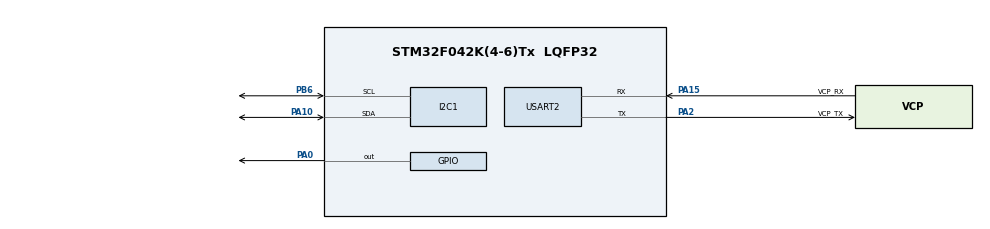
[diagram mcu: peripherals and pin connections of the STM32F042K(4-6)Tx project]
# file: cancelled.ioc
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Mcu.Family=STM32F0
Mcu.Name=STM32F042K(4-6)Tx
Mcu.Package=LQFP32
NVIC.TIM1_BRK_UP_TRG_COM_IRQn=true\:0\:0\:false\:false\:true\:false\:true
NVIC.TimeBase=TIM1_BRK_UP_TRG_COM_IRQn
NVIC.TimeBaseIP=TIM1
PA0.Signal=GPIO_Output
PA10.Mode=I2C
PA10.Signal=I2C1_SDA
PA13.GPIO_Label=SWDIO
PA13.Mode=Serial_Wire
PA13.Signal=SYS_SWDIO
PA14.GPIO_Label=SWCLK
PA14.Mode=Serial_Wire
PA14.Signal=SYS_SWCLK
PA15.GPIO_Label=VCP_RX
PA15.Mode=Asynchronous
PA15.Signal=USART2_RX
PA2.GPIO_Label=VCP_TX
PA2.Mode=Asynchronous
PA2.Signal=USART2_TX
PB6.Mode=I2C
PB6.Signal=I2C1_SCL
PF0-OSC_IN.GPIO_Label=MCO
PF0-OSC_IN.Mode=HSE-External-Clock-Source
PF0-OSC_IN.Signal=RCC_OSC_IN
ProjectManager.HeapSize=0x200
ProjectManager.StackSize=0x400
ProjectManager.TargetToolchain=STM32CubeIDE
USART2.VirtualMode-Asynchronous=VM_ASYNC
VP_SYS_VS_tim1.Mode=TIM1
board=NUCLEO-F042K6

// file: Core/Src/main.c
/* USER CODE BEGIN Header */
/**
  ******************************************************************************
  * @file           : main.c
  * @brief          : Main program body
  ******************************************************************************
  * @attention
  *
  * <h2><center>&copy; Copyright (c) 2020 STMicroelectronics.
  * All rights reserved.</center></h2>
  *
  * This software component is licensed by ST under BSD 3-Clause license,
  * the "License"; You may not use this file except in compliance with the
  * License. You may obtain a copy of the License at:
  *                        opensource.org/licenses/BSD-3-Clause
  *
  ******************************************************************************
  */
/* USER CODE END Header */

#include "main.h"

/* USER CODE BEGIN Includes */
#include "matrix.h"
#include "conway.h"
#include "random.h"
#include "rotate.h"
#include "doggo.h"
/* USER CODE END Includes */

I2C_HandleTypeDef hi2c1;

UART_HandleTypeDef huart2;

/* USER CODE BEGIN PV */
uint8_t* active_fbuf;
uint8_t* next_fbuf;
/* USER CODE END PV */

void SystemClock_Config(void);
static void MX_GPIO_Init(void);
static void MX_USART2_UART_Init(void);
static void MX_I2C1_Init(void);

int main(void)
{

  /* MCU Configuration--------------------------------------------------------*/

  /* Reset of all peripherals, Initializes the Flash interface and the Systick. */
  HAL_Init();

  /* Configure the system clock */
  SystemClock_Config();

  /* Initialize all configured peripherals */
  MX_GPIO_Init();
  MX_USART2_UART_Init();
  MX_I2C1_Init();
  /* USER CODE BEGIN 2 */
  init_matrix(&hi2c1);
  init_accel(&hi2c1);
  /* USER CODE END 2 */

  /* Infinite loop */
  while (1)
  {

    /* USER CODE BEGIN 3 */
	  doggo_demo(&hi2c1);
	  conway_demo(&hi2c1);
	  rotate_demo(&hi2c1);

  }
  /* USER CODE END 3 */
}

void SystemClock_Config(void)
{
  RCC_OscInitTypeDef RCC_OscInitStruct = {0};
  RCC_ClkInitTypeDef RCC_ClkInitStruct = {0};
  RCC_PeriphCLKInitTypeDef PeriphClkInit = {0};

  /** Initializes the CPU, AHB and APB busses clocks
  */
  RCC_OscInitStruct.OscillatorType = RCC_OSCILLATORTYPE_HSI;
  RCC_OscInitStruct.HSIState = RCC_HSI_ON;
  RCC_OscInitStruct.HSICalibrationValue = RCC_HSICALIBRATION_DEFAULT;
  RCC_OscInitStruct.PLL.PLLState = RCC_PLL_NONE;
  if (HAL_RCC_OscConfig(&RCC_OscInitStruct) != HAL_OK)
  {
    Error_Handler();
  }
  /** Initializes the CPU, AHB and APB busses clocks
  */
  RCC_ClkInitStruct.ClockType = RCC_CLOCKTYPE_HCLK|RCC_CLOCKTYPE_SYSCLK
                              |RCC_CLOCKTYPE_PCLK1;
  RCC_ClkInitStruct.SYSCLKSource = RCC_SYSCLKSOURCE_HSI;
  RCC_ClkInitStruct.AHBCLKDivider = RCC_SYSCLK_DIV1;
  RCC_ClkInitStruct.APB1CLKDivider = RCC_HCLK_DIV1;

  if (HAL_RCC_ClockConfig(&RCC_ClkInitStruct, FLASH_LATENCY_0) != HAL_OK)
  {
    Error_Handler();
  }
  PeriphClkInit.PeriphClockSelection = RCC_PERIPHCLK_I2C1;
  PeriphClkInit.I2c1ClockSelection = RCC_I2C1CLKSOURCE_HSI;
  if (HAL_RCCEx_PeriphCLKConfig(&PeriphClkInit) != HAL_OK)
  {
    Error_Handler();
  }
}

static void MX_I2C1_Init(void)
{

  hi2c1.Instance = I2C1;
  hi2c1.Init.Timing = 0x2000090E;
  hi2c1.Init.OwnAddress1 = 0;
  hi2c1.Init.AddressingMode = I2C_ADDRESSINGMODE_7BIT;
  hi2c1.Init.DualAddressMode = I2C_DUALADDRESS_DISABLE;
  hi2c1.Init.OwnAddress2 = 0;
  hi2c1.Init.OwnAddress2Masks = I2C_OA2_NOMASK;
  hi2c1.Init.GeneralCallMode = I2C_GENERALCALL_DISABLE;
  hi2c1.Init.NoStretchMode = I2C_NOSTRETCH_DISABLE;
  if (HAL_I2C_Init(&hi2c1) != HAL_OK)
  {
    Error_Handler();
  }
  /** Configure Analogue filter
  */
  if (HAL_I2CEx_ConfigAnalogFilter(&hi2c1, I2C_ANALOGFILTER_ENABLE) != HAL_OK)
  {
    Error_Handler();
  }
  /** Configure Digital filter
  */
  if (HAL_I2CEx_ConfigDigitalFilter(&hi2c1, 0) != HAL_OK)
  {
    Error_Handler();
  }

}

static void MX_USART2_UART_Init(void)
{

  huart2.Instance = USART2;
  huart2.Init.BaudRate = 38400;
  huart2.Init.WordLength = UART_WORDLENGTH_8B;
  huart2.Init.StopBits = UART_STOPBITS_1;
  huart2.Init.Parity = UART_PARITY_NONE;
  huart2.Init.Mode = UART_MODE_TX_RX;
  huart2.Init.HwFlowCtl = UART_HWCONTROL_NONE;
  huart2.Init.OverSampling = UART_OVERSAMPLING_16;
  huart2.Init.OneBitSampling = UART_ONE_BIT_SAMPLE_DISABLE;
  huart2.AdvancedInit.AdvFeatureInit = UART_ADVFEATURE_NO_INIT;
  if (HAL_UART_Init(&huart2) != HAL_OK)
  {
    Error_Handler();
  }

}

static void MX_GPIO_Init(void)
{
  GPIO_InitTypeDef GPIO_InitStruct = {0};

  /* GPIO Ports Clock Enable */
  __HAL_RCC_GPIOF_CLK_ENABLE();
  __HAL_RCC_GPIOA_CLK_ENABLE();
  __HAL_RCC_GPIOB_CLK_ENABLE();

  /*Configure GPIO pin Output Level */
  HAL_GPIO_WritePin(GPIOA, GPIO_PIN_0, GPIO_PIN_RESET);

  /*Configure GPIO pin : PA0 */
  GPIO_InitStruct.Pin = GPIO_PIN_0;
  GPIO_InitStruct.Mode = GPIO_MODE_OUTPUT_PP;
  GPIO_InitStruct.Pull = GPIO_NOPULL;
  GPIO_InitStruct.Speed = GPIO_SPEED_FREQ_LOW;
  HAL_GPIO_Init(GPIOA, &GPIO_InitStruct);

}

void HAL_TIM_PeriodElapsedCallback(TIM_HandleTypeDef *htim)
{
  if (htim->Instance == TIM1) {
    HAL_IncTick();
  }
}

void Error_Handler(void)
{
}

/************************ (C) COPYRIGHT STMicroelectronics *****END OF FILE****/
